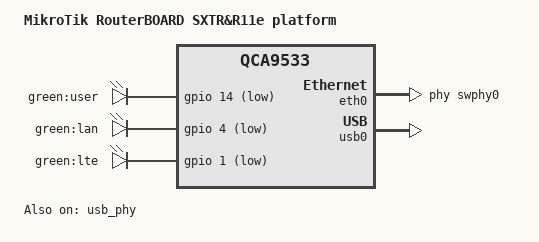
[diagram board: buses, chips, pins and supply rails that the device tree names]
// SPDX-License-Identifier: GPL-2.0-or-later OR MIT

#include "qca9533_mikrotik_routerboard-16m.dtsi"

/ {
	compatible = "mikrotik,routerboard-sxtr", "qca,qca9533";
	model = "MikroTik RouterBOARD SXTR&R11e platform";

	aliases {
		led-boot = &led_user;
		led-failsafe = &led_user;
		led-upgrade = &led_user;
		led-running = &led_user;
	};

	leds {
		compatible = "gpio-leds";
		pinctrl-names = "default";
		pinctrl-0 = <&led_wan_pin>;


		led_user: user {
			label = "green:user";
			gpios = <&gpio 14 GPIO_ACTIVE_LOW>;
		}; 

		lan {
			label = "green:lan";
			gpios = <&gpio 4 GPIO_ACTIVE_LOW>;
		};

/*		sigall {
			label = "green:sigall";
			gpios = <&gpio 11 GPIO_ACTIVE_LOW>;
		}; */
		
		lte {
			label = "green:lte";
			gpios = <&gpio 1 GPIO_ACTIVE_LOW>;
		};

	/*	rssilow {
			label = "green:rssilow";
			gpios = <&gpio 9 GPIO_ACTIVE_LOW>;
		};

		rssimediumlow {
			label = "green:rssimediumlow";
			gpios = <&gpio 12 GPIO_ACTIVE_LOW>;
		};

		rssimediumhigh {
			label = "green:rssimediumhigh";
			gpios = <&gpio 13 GPIO_ACTIVE_LOW>;
		};

		 The rssihigh LED GPIO 16 is shared with the reset button, so it remains
		unregistered here to avoid conflict.

		rssihigh {
			label = "green:rssihigh";
			gpios = <&gpio 16 GPIO_ACTIVE_LOW>;
		};
		*/
	};
};

&eth0 {
	status = "okay";

	phy-handle = <&swphy0>;

	gmac-config {
		device = <&gmac>;
		switch-phy-swap = <1>;
	};
};

&eth1 {
	compatible = "syscon", "simple-mfd";
};

&usb0 {
	status = "okay";
};

&usb_phy {
	status = "okay";
};

&pinmux {
	led_wan_pin: pinmux_led_wan_pin {
		pinctrl-single,bits = <0x4 0x0 0xff>;
	};
};
